# PCIE_CFG_TYPE1 register map
Vendor: Texas Instruments
Peripheral module from a debugger description file (folder 66AK2G0x_66AK2G1x).
Registers are 32-bit, access per field, reset 0x0 unless marked. A register's access mark holds for its fields unless they carry their own. Offsets are as the file gives them; lines under a group give offsets from that group; [hi:lo] are bit positions; {n}, {i} and the like mark numbered series; 'fields as' and 'values as' point back to an identical list; <NAME> marks a mode.

## PCIE_CFG_TYPE1
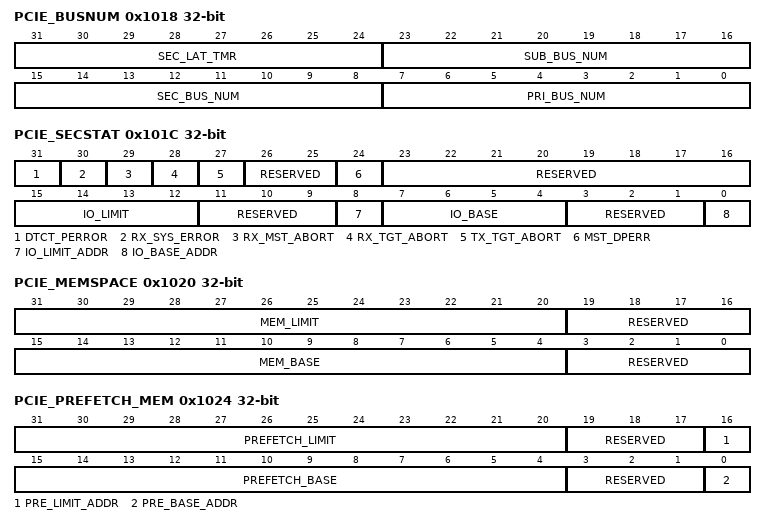
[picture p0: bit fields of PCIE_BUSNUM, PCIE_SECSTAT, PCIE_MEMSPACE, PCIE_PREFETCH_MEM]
0x1018 PCIE_BUSNUM
  [31:24] SEC_LAT_TMR ro — Secondary Latency Timer. Not applicable in PCI Express
  [23:16] SUB_BUS_NUM rw — Subordinate Bus Number. This is highest bus number on downstream interface.
  [15:8] SEC_BUS_NUM rw — Secondary Bus Number. It is typically 1h for RC.
  [7:0] PRI_BUS_NUM rw — Primary Bus Number. It is 0 for RC and nonzero for switch devices only.
0x101C PCIE_SECSTAT access not given
  [31] DTCT_PERROR — Detected Parity Error. Set if the function receives a poisoned TLP. (access RW1C)
  [30] RX_SYS_ERROR — Received System Error. Set if the function receives an ERR_FATAL or ERR_NONFATAL message. (access RW1C)
  [29] RX_MST_ABORT — Received Master Abort. Set if the function receives a completion with unsupported request completion status. (access RW1C)
  [28] RX_TGT_ABORT — Received Target Abort. Set if the function receives a completion with completer abort completion status. (access RW1C)
  [27] TX_TGT_ABORT — Signaled Target Abort. Set if the function completes a posted or non-posted request as a completer abort error. (access RW1C)
  [26:25] RESERVED ro — Reads return 0 and writes have no effect.
  [24] MST_DPERR — Master Data Parity Error. Set if the parity error enable bit is set in the Bridge Control Register and either the condition that the requester receives a poisoned completion or the condition that the requester poisons a write request is true. (access RW1C)
  [23:16] RESERVED ro — Reads return 0 and writes have no effect.
  [15:12] IO_LIMIT rw — Upper 4 bits of 16bit IO Space Limit Address.
  [11:9] RESERVED ro — Reads return 0 and writes have no effect.
  [8] IO_LIMIT_ADDR ro — Indicates addressing for IO Limit Address. Writable from internal bus interface.
  [7:4] IO_BASE rw — Upper 4 bits of 16bit IO Space Base Address.
  [3:1] RESERVED ro — Reads return 0 and writes have no effect.
  [0] IO_BASE_ADDR ro — Indicates addressing for the IO Base Address. Writable from internal bus interface.
0x1020 PCIE_MEMSPACE
  [31:20] MEM_LIMIT rw — Upper 12 bits of 32bit Memory Limit Address.
  [19:16] RESERVED ro — Reads return 0 and writes have no effect.
  [15:4] MEM_BASE rw — Upper 12 bits of 32bit Memory Base Address.
  [3:0] RESERVED ro — Reads return 0 and writes have no effect.
0x1024 PCIE_PREFETCH_MEM
  [31:20] PREFETCH_LIMIT rw — Upper 12 bits of 32bit prefetchable memory limit address (end address).
  [19:17] RESERVED ro — Reads return 0 and writes have no effect.
  [16] PRE_LIMIT_ADDR ro — Indicates addressing for prefetchable memory limit address (end address). Writable from internal bus interface.
  [15:4] PREFETCH_BASE ro — Upper 12 bits of 32bit prefetchable memory base address (start address).
  [3:1] RESERVED ro — Reads return 0 and writes have no effect.
  [0] PRE_BASE_ADDR ro — Indicates addressing for the prefetchable memory base address (start address). Writable from internal bus interface.
0x1028 PCIE_PREFETCH_BASE rw
  [31:0] PREFETCH_BASE — Upper 32 bits of Prefetchable Memory Base Address. Used with 64bit prefetchable memory addressing only.
0x102C PCIE_PREFETCH_LIMIT rw
  [31:0] PREFETCH_LIMIT — Upper 32 bits of Prefetchable Memory Limit Address. Used with 64 bit prefetchable memory addressing only.
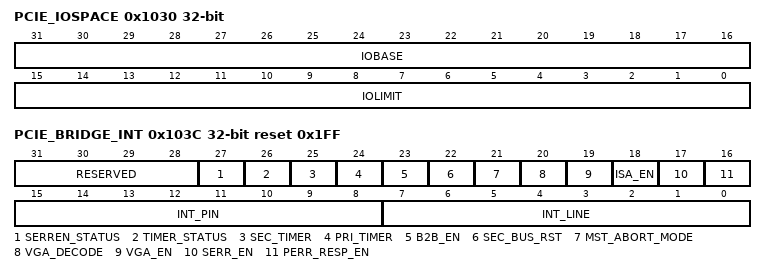
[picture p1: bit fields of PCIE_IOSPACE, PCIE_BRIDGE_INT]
0x1030 PCIE_IOSPACE rw
  [31:16] IOBASE — Upper 16 bits of IO Base Address. Used with 32 bit IO space addressing only.
  [15:0] IOLIMIT — Upper 16 bits of IO Limit Address. Used with 32 bit IO space addressing only.
0x103C PCIE_BRIDGE_INT reset 0x1FF
  [31:28] RESERVED ro — Reads return 0 and writes have no effect.
  [27] SERREN_STATUS ro — Discard Timer SERR Enable Status. Not Applicable to PCI Express. Hardwired to 0.
  [26] TIMER_STATUS ro — Discard Timer Status. Not applicable to PCI Express. Hardwired to 0.
  [25] SEC_TIMER ro — Secondary Discard Timer. Not applicable to PCI Express. Hardwired to 0.
  [24] PRI_TIMER ro — Primary Discard Timer. Not applicable to PCI Express. Hardwired to 0.
  [23] B2B_EN ro — Fast Back to Back Transactions Enable. Not applicable to PCI Express. Hardwired to 0.
  [22] SEC_BUS_RST rw — Secondary Bus Reset.
  [21] MST_ABORT_MODE ro — Master Abort Mode. Not applicable to PCI Express. Hardwired to 0.
  [20] VGA_DECODE rw — VGA 16 bit Decode
  [19] VGA_EN rw — VGA Enable
  [18] ISA_EN rw — ISA Enable
  [17] SERR_EN rw — SERR Enable. Set to enable forwarding of ERR_COR, ERR_NONFATAL and ERR_FATAL messages.
  [16] PERR_RESP_EN rw — Parity Error Response Enable. This bit controls the logging of poisoned TLPs in the Master Data Parity Error bit in the Secondary Status Register.
  [15:8] INT_PIN ro — Interrupt Pin. It identifies the legacy interrupt message that the device uses. For single function configuration, the core only uses INTA. This register is writable through internal bus interface.
  [7:0] INT_LINE rw — Interrupt Line. Value is system software specified.
